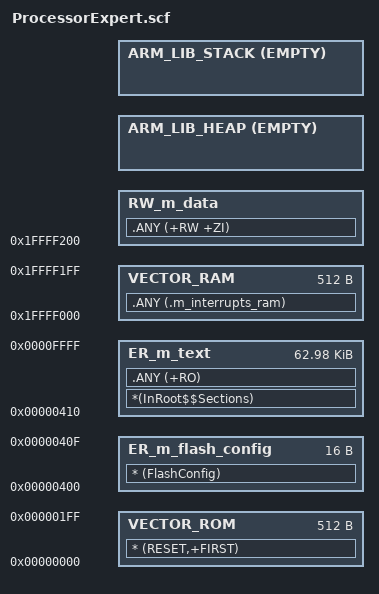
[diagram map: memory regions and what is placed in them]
#! armcc -E -D__stack_size__=0x0400 -D__heap_size__=0x0000
;## #######################################################################
;##                                                
;##     THIS COMPONENT MODULE IS GENERATED. DO NOT MODIFY IT.
;##                                                
;##     Filename  : ProcessorExpert.scf                
;##                                                
;##     Project   : KL27Chainsaw                   
;##                                                
;##     Processor : MKL27Z64VLH4                    
;##                                                
;##     Compiler  : Keil ARM C/C++ Compiler                    
;##                                                
;##     Date/Time : 2016-11-11, 11:57, # CodeGen: 0                     
;##                                                
;##     Abstract  :                                
;##                                                
;##     This file is used by the linker. It describes files to be linked,
;##     memory ranges, stack size, etc. For detailed description about
;##     linker command files see compiler documentation. This file 
;##     is generated by default. You can switch off generation by setting
;##     the property "Generate linker file = no" in the "Build options"
;##     tab of the CPU component and then modify this file as needed.
;##                                                
;##                                                
;## #######################################################################

#define m_interrupts_start              0x00000000
#define m_interrupts_size               0x00000200
    
#define m_flash_config_start            0x00000400
#define m_flash_config_size             0x00000010

#define m_interrupts_ram_start          0x1FFFF000
#define m_interrupts_ram_size           0x00000200
    
#define m_text_start                    0x00000410
#define m_text_size                     0x0000FBF0
    
#define m_data_start                    0x1FFFF200
#define m_data_size                     0x00003E00
    
/*-Sizes-*/
#define Stack_Size                      __stack_size__
#define Heap_Size                       __heap_size__
 
LR_m_text m_text_start m_text_size  {  ; load region size_region
  ER_m_text m_text_start m_text_size  { ; load address = execution address
   *(InRoot$$Sections)
   .ANY (+RO)
  }
  RW_m_data m_data_start m_data_size-Stack_Size-Heap_Size  {
   .ANY (+RW +ZI)
  }
  ARM_LIB_HEAP +0 EMPTY Heap_Size {    ; Heap region growing up
  }
  ARM_LIB_STACK m_data_start+m_data_size EMPTY -Stack_Size { ; Stack region growing down
  }
}

LR_m_interrupts m_interrupts_start m_interrupts_size  {
  VECTOR_ROM m_interrupts_start m_interrupts_size  { ; load address = execution address
   * (RESET,+FIRST)
  }
}

LR_m_flash_config m_flash_config_start m_flash_config_size  {
  ER_m_flash_config m_flash_config_start m_flash_config_size  { ; load address = execution address
   * (FlashConfig)
  }
}

LR_m_interrupts_ram m_interrupts_ram_start m_interrupts_ram_size  {
  VECTOR_RAM m_interrupts_ram_start m_interrupts_ram_size  { ; load address = execution address
   .ANY (.m_interrupts_ram)
  }
}


